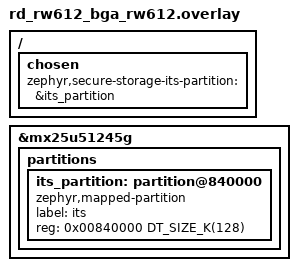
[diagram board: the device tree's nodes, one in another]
/*
 * Copyright 2024-2026 NXP
 *
 * SPDX-License-Identifier: Apache-2.0
 */

/ {
	chosen {
		zephyr,secure-storage-its-partition = &its_partition;
	};
};

&mx25u51245g {
	partitions {
		/delete-node/ partition@760000;

		its_partition: partition@840000 {
			compatible = "zephyr,mapped-partition";
			label = "its";
			reg = <0x00840000 DT_SIZE_K(128)>;
		};
	};
};
